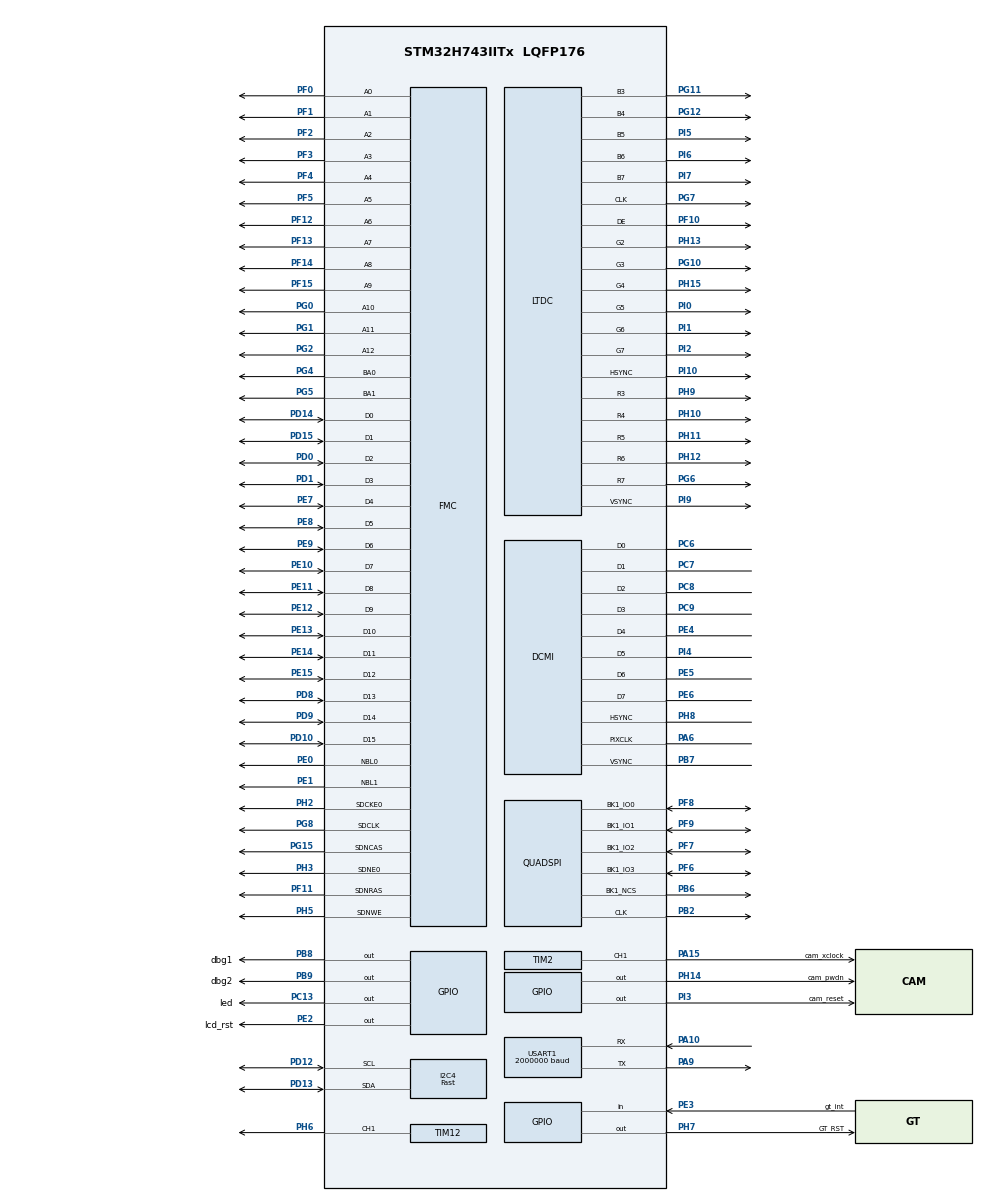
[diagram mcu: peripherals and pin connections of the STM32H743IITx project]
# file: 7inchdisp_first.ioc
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CORTEX_M7.AccessPermission_S-Cortex_Memory_Protection_Unit_Region1_Settings_S=MPU_REGION_FULL_ACCESS
CORTEX_M7.AccessPermission_S-Cortex_Memory_Protection_Unit_Region2_Settings_S=MPU_REGION_FULL_ACCESS
CORTEX_M7.BaseAddress_S-Cortex_Memory_Protection_Unit_Region1_Settings_S=0xc0000000
CORTEX_M7.BaseAddress_S-Cortex_Memory_Protection_Unit_Region2_Settings_S=0x90000000
CORTEX_M7.CPU_DCache=Enabled
CORTEX_M7.CPU_ICache=Enabled
CORTEX_M7.Enable_S-Cortex_Memory_Protection_Unit_Region1_Settings_S=MPU_REGION_ENABLE
CORTEX_M7.Enable_S-Cortex_Memory_Protection_Unit_Region2_Settings_S=MPU_REGION_ENABLE
CORTEX_M7.IsBufferable_S-Cortex_Memory_Protection_Unit_Region1_Settings_S=MPU_ACCESS_BUFFERABLE
CORTEX_M7.IsBufferable_S-Cortex_Memory_Protection_Unit_Region2_Settings_S=MPU_ACCESS_BUFFERABLE
CORTEX_M7.IsCacheable_S-Cortex_Memory_Protection_Unit_Region1_Settings_S=MPU_ACCESS_CACHEABLE
CORTEX_M7.IsCacheable_S-Cortex_Memory_Protection_Unit_Region2_Settings_S=MPU_ACCESS_CACHEABLE
CORTEX_M7.Size_S-Cortex_Memory_Protection_Unit_Region1_Settings_S=MPU_REGION_SIZE_32MB
CORTEX_M7.Size_S-Cortex_Memory_Protection_Unit_Region2_Settings_S=MPU_REGION_SIZE_16MB
CORTEX_M7.default_mode_Activation=1
DCMI.PCKPolarity=DCMI_PCKPOLARITY_RISING
DCMI.VSPolarity=DCMI_VSPOLARITY_HIGH
DMA2D.ColorMode=DMA2D_OUTPUT_RGB565
Dma.DCMI.1.Direction=DMA_PERIPH_TO_MEMORY
Dma.DCMI.1.EventEnable=DISABLE
Dma.DCMI.1.FIFOMode=DMA_FIFOMODE_ENABLE
Dma.DCMI.1.FIFOThreshold=DMA_FIFO_THRESHOLD_FULL
Dma.DCMI.1.Instance=DMA1_Stream1
Dma.DCMI.1.MemBurst=DMA_MBURST_INC4
Dma.DCMI.1.MemDataAlignment=DMA_MDATAALIGN_WORD
Dma.DCMI.1.MemInc=DMA_MINC_ENABLE
Dma.DCMI.1.Mode=DMA_CIRCULAR
Dma.DCMI.1.PeriphBurst=DMA_PBURST_SINGLE
Dma.DCMI.1.PeriphDataAlignment=DMA_PDATAALIGN_WORD
Dma.DCMI.1.PeriphInc=DMA_PINC_DISABLE
Dma.DCMI.1.Polarity=HAL_DMAMUX_REQ_GEN_RISING
Dma.DCMI.1.Priority=DMA_PRIORITY_VERY_HIGH
Dma.DCMI.1.RequestNumber=1
Dma.DCMI.1.SignalID=NONE
Dma.DCMI.1.SyncEnable=DISABLE
Dma.DCMI.1.SyncPolarity=HAL_DMAMUX_SYNC_NO_EVENT
Dma.DCMI.1.SyncRequestNumber=1
Dma.DCMI.1.SyncSignalID=NONE
Dma.Request0=USART1_RX
Dma.Request1=DCMI
Dma.USART1_RX.0.Direction=DMA_PERIPH_TO_MEMORY
Dma.USART1_RX.0.EventEnable=DISABLE
Dma.USART1_RX.0.FIFOMode=DMA_FIFOMODE_ENABLE
Dma.USART1_RX.0.FIFOThreshold=DMA_FIFO_THRESHOLD_FULL
Dma.USART1_RX.0.Instance=DMA1_Stream0
Dma.USART1_RX.0.MemBurst=DMA_MBURST_SINGLE
Dma.USART1_RX.0.MemDataAlignment=DMA_MDATAALIGN_BYTE
Dma.USART1_RX.0.MemInc=DMA_MINC_ENABLE
Dma.USART1_RX.0.Mode=DMA_NORMAL
Dma.USART1_RX.0.PeriphBurst=DMA_PBURST_SINGLE
Dma.USART1_RX.0.PeriphDataAlignment=DMA_PDATAALIGN_BYTE
Dma.USART1_RX.0.PeriphInc=DMA_PINC_DISABLE
Dma.USART1_RX.0.Polarity=HAL_DMAMUX_REQ_GEN_RISING
Dma.USART1_RX.0.Priority=DMA_PRIORITY_LOW
Dma.USART1_RX.0.RequestNumber=1
Dma.USART1_RX.0.SignalID=NONE
Dma.USART1_RX.0.SyncEnable=DISABLE
Dma.USART1_RX.0.SyncPolarity=HAL_DMAMUX_SYNC_NO_EVENT
Dma.USART1_RX.0.SyncRequestNumber=1
Dma.USART1_RX.0.SyncSignalID=NONE
FMC.CASLatency1=FMC_SDRAM_CAS_LATENCY_3
FMC.ColumnBitsNumber1=FMC_SDRAM_COLUMN_BITS_NUM_9
FMC.ExitSelfRefreshDelay1=7
FMC.LoadToActiveDelay1=2
FMC.RCDDelay1=2
FMC.RPDelay1=2
FMC.RPDelay2=2
FMC.ReadBurst1=FMC_SDRAM_RBURST_ENABLE
FMC.ReadBurst2=FMC_SDRAM_RBURST_ENABLE
FMC.ReadPipeDelay1=FMC_SDRAM_RPIPE_DELAY_1
FMC.ReadPipeDelay2=FMC_SDRAM_RPIPE_DELAY_1
FMC.RowCycleDelay1=7
FMC.RowCycleDelay2=7
FMC.SDClockPeriod1=FMC_SDRAM_CLOCK_PERIOD_2
FMC.SDClockPeriod2=FMC_SDRAM_CLOCK_PERIOD_2
FMC.SelfRefreshTime1=5
FMC.WriteRecoveryTime1=3
I2C4.I2C_Speed_Mode=I2C_Fast
I2C4.Timing=0x009034B6
LTDC.ActiveH=600
LTDC.ActiveW=1024
LTDC.Alpha_L0=255
LTDC.DEPolarity=LTDC_DEPOLARITY_AL
LTDC.FBStartAdress_L0=0xc0000000
LTDC.Green=255
LTDC.HBP=40
LTDC.HFP=31
LTDC.HSync=10
LTDC.ImageHeight_L0=600
LTDC.ImageWidth_L0=1024
LTDC.Layers=0
LTDC.PCPolarity=LTDC_PCPOLARITY_IPC
LTDC.PixelFormat_L0=LTDC_PIXEL_FORMAT_RGB565
LTDC.Red_L0=255
LTDC.VBP=20
LTDC.VFP=10
LTDC.VSync=5
LTDC.WindowX1_L0=1024
LTDC.WindowY1_L0=600
Mcu.Family=STM32H7
Mcu.Name=STM32H743IITx
Mcu.Package=LQFP176
NVIC.DCMI_IRQn=true\:0\:0\:false\:false\:true\:true\:true\:true
NVIC.DMA1_Stream0_IRQn=true\:0\:0\:false\:false\:true\:false\:true\:true
NVIC.DMA1_Stream1_IRQn=true\:0\:0\:false\:false\:true\:false\:true\:true
NVIC.PriorityGroup=NVIC_PRIORITYGROUP_4
NVIC.QUADSPI_IRQn=true\:0\:0\:false\:false\:true\:true\:true\:true
PA10.Mode=Asynchronous
PA10.Signal=USART1_RX
PA13\ (JTMS/SWDIO).Mode=Trace_Asynchronous_SW
PA13\ (JTMS/SWDIO).Signal=DEBUG_JTMS-SWDIO
PA14\ (JTCK/SWCLK).Mode=Trace_Asynchronous_SW
PA14\ (JTCK/SWCLK).Signal=DEBUG_JTCK-SWCLK
PA15\ (JTDI).GPIO_Label=cam_xclock
PA15\ (JTDI).GPIO_Speed=GPIO_SPEED_FREQ_HIGH
PA15\ (JTDI).Signal=S_TIM2_CH1_ETR
PA6.Mode=Slave_8_bits_External_Synchro
PA6.Signal=DCMI_PIXCLK
PA9.Mode=Asynchronous
PA9.Signal=USART1_TX
PB2.GPIO_Speed=GPIO_SPEED_FREQ_VERY_HIGH
PB2.Mode=Single Bank 1
PB2.Signal=QUADSPI_CLK
PB3\ (JTDO/TRACESWO).Mode=Trace_Asynchronous_SW
PB3\ (JTDO/TRACESWO).Signal=DEBUG_JTDO-SWO
PB6.GPIO_FM6=__NULL
PB6.GPIO_Speed=GPIO_SPEED_FREQ_VERY_HIGH
PB6.Mode=Single Bank 1
PB6.Signal=QUADSPI_BK1_NCS
PB7.Mode=Slave_8_bits_External_Synchro
PB7.Signal=DCMI_VSYNC
PB8.GPIO_Label=dbg1
PB8.Signal=GPIO_Output
PB9.GPIO_Label=dbg2
PB9.Signal=GPIO_Output
PC13.GPIO_Label=led
PC13.Signal=GPIO_Output
PC6.Mode=Slave_8_bits_External_Synchro
PC6.Signal=DCMI_D0
PC7.Mode=Slave_8_bits_External_Synchro
PC7.Signal=DCMI_D1
PC8.Mode=Slave_8_bits_External_Synchro
PC8.Signal=DCMI_D2
PC9.Mode=Slave_8_bits_External_Synchro
PC9.Signal=DCMI_D3
PD0.Signal=FMC_D2_DA2
PD1.Signal=FMC_D3_DA3
PD10.Signal=FMC_D15_DA15
PD12.Mode=I2C
PD12.Signal=I2C4_SCL
PD13.Mode=I2C
PD13.Signal=I2C4_SDA
PD14.Signal=FMC_D0_DA0
PD15.Signal=FMC_D1_DA1
PD8.Signal=FMC_D13_DA13
PD9.Signal=FMC_D14_DA14
PE0.Signal=FMC_NBL0
PE1.Signal=FMC_NBL1
PE10.Signal=FMC_D7_DA7
PE11.Signal=FMC_D8_DA8
PE12.Signal=FMC_D9_DA9
PE13.Signal=FMC_D10_DA10
PE14.Signal=FMC_D11_DA11
PE15.Signal=FMC_D12_DA12
PE2.GPIO_Label=lcd_rst
PE2.Signal=GPIO_Output
PE3.GPIO_Label=gt_int
PE3.Signal=GPIO_Input
PE4.Mode=Slave_8_bits_External_Synchro
PE4.Signal=DCMI_D4
PE5.Mode=Slave_8_bits_External_Synchro
PE5.Signal=DCMI_D6
PE6.Mode=Slave_8_bits_External_Synchro
PE6.Signal=DCMI_D7
PE7.Signal=FMC_D4_DA4
PE8.Signal=FMC_D5_DA5
PE9.Signal=FMC_D6_DA6
PF0.Signal=FMC_A0
PF1.Signal=FMC_A1
PF10.Mode=RGB565
PF10.Signal=LTDC_DE
PF11.Signal=FMC_SDNRAS
PF12.Signal=FMC_A6
PF13.Signal=FMC_A7
PF14.Signal=FMC_A8
PF15.Signal=FMC_A9
PF2.Signal=FMC_A2
PF3.Signal=FMC_A3
PF4.Signal=FMC_A4
PF5.Signal=FMC_A5
PF6.GPIO_Speed=GPIO_SPEED_FREQ_VERY_HIGH
PF6.Mode=Single Bank 1
PF6.Signal=QUADSPI_BK1_IO3
PF7.GPIO_Speed=GPIO_SPEED_FREQ_VERY_HIGH
PF7.Mode=Single Bank 1
PF7.Signal=QUADSPI_BK1_IO2
PF8.GPIO_Speed=GPIO_SPEED_FREQ_VERY_HIGH
PF8.Mode=Single Bank 1
PF8.Signal=QUADSPI_BK1_IO0
PF9.GPIO_Speed=GPIO_SPEED_FREQ_VERY_HIGH
PF9.Mode=Single Bank 1
PF9.Signal=QUADSPI_BK1_IO1
PG0.Signal=FMC_A10
PG1.Signal=FMC_A11
PG10.Mode=RGB565
PG10.Signal=LTDC_G3
PG11.Mode=RGB565
PG11.Signal=LTDC_B3
PG12.Mode=RGB565
PG12.Signal=LTDC_B4
PG15.Signal=FMC_SDNCAS
PG2.Signal=FMC_A12
PG4.Signal=FMC_A14_BA0
PG5.Signal=FMC_A15_BA1
PG6.Mode=RGB565
PG6.Signal=LTDC_R7
PG7.Mode=RGB565
PG7.Signal=LTDC_CLK
PG8.Signal=FMC_SDCLK
PH0-OSC_IN\ (PH0).Mode=HSE-External-Oscillator
PH0-OSC_IN\ (PH0).Signal=RCC_OSC_IN
PH1-OSC_OUT\ (PH1).Mode=HSE-External-Oscillator
PH1-OSC_OUT\ (PH1).Signal=RCC_OSC_OUT
PH10.Mode=RGB565
PH10.Signal=LTDC_R4
PH11.Mode=RGB565
PH11.Signal=LTDC_R5
PH12.Mode=RGB565
PH12.Signal=LTDC_R6
PH13.Mode=RGB565
PH13.Signal=LTDC_G2
PH14.GPIO_Label=cam_pwdn
PH14.Signal=GPIO_Output
PH15.Mode=RGB565
PH15.Signal=LTDC_G4
PH2.Mode=SdramChipSelect1_1
PH2.Signal=FMC_SDCKE0
PH3.Mode=SdramChipSelect1_1
PH3.Signal=FMC_SDNE0
PH5.Signal=FMC_SDNWE
PH6.Signal=S_TIM12_CH1
PH7.GPIO_Label=GT_RST
PH7.Signal=GPIO_Output
PH8.Mode=Slave_8_bits_External_Synchro
PH8.Signal=DCMI_HSYNC
PH9.Mode=RGB565
PH9.Signal=LTDC_R3
PI0.Mode=RGB565
PI0.Signal=LTDC_G5
PI1.Mode=RGB565
PI1.Signal=LTDC_G6
PI10.Mode=RGB565
PI10.Signal=LTDC_HSYNC
PI2.Mode=RGB565
PI2.Signal=LTDC_G7
PI3.GPIO_Label=cam_reset
PI3.Signal=GPIO_Output
PI4.Mode=Slave_8_bits_External_Synchro
PI4.Signal=DCMI_D5
PI5.Mode=RGB565
PI5.Signal=LTDC_B5
PI6.Mode=RGB565
PI6.Signal=LTDC_B6
PI7.Mode=RGB565
PI7.Signal=LTDC_B7
PI9.Mode=RGB565
PI9.Signal=LTDC_VSYNC
ProjectManager.HeapSize=0x200
ProjectManager.StackSize=0x400
ProjectManager.TargetToolchain=STM32CubeIDE
QUADSPI.ChipSelectHighTime=QSPI_CS_HIGH_TIME_2_CYCLE
QUADSPI.ClockPrescaler=1
QUADSPI.FifoThreshold=32
QUADSPI.FlashSize=23
QUADSPI.SampleShifting=QSPI_SAMPLE_SHIFTING_HALFCYCLE
RCC.ADCCLockSelection=RCC_ADCCLKSOURCE_PLL2
RCC.ADCFreq_Value=50390625
RCC.APB1Freq_Value=100000000
RCC.APB2Freq_Value=100000000
RCC.APB3Freq_Value=100000000
RCC.APB4Freq_Value=100000000
RCC.CECCLockSelection=RCC_CECCLKSOURCE_LSI
RCC.CKPERSourceSelection=RCC_CLKPSOURCE_HSI
RCC.CSI_VALUE=4000000
RCC.CortexFreq_Value=400000000
RCC.Cortex_Div=SYSTICK_CLKSOURCE_HCLK
RCC.Cortex_DivARG=SystemCoreClock/1000
RCC.D1CPRE=RCC_SYSCLK_DIV1
RCC.D1PPRE=RCC_APB3_DIV2
RCC.D2PPRE1=RCC_APB1_DIV2
RCC.D2PPRE2=RCC_APB2_DIV2
RCC.D3PPRE=RCC_APB4_DIV2
RCC.DFSDMCLockSelection=RCC_DFSDM1CLKSOURCE_D2PCLK1
RCC.DIVM1=5
RCC.DIVM2=32
RCC.DIVM3=5
RCC.DIVN1=160
RCC.DIVN2=129
RCC.DIVN3=159
RCC.DIVP1=2
RCC.DIVP2=2
RCC.DIVP3=2
RCC.DIVQ1=4
RCC.DIVQ2=2
RCC.DIVQ3=2
RCC.DIVR1=2
RCC.DIVR2=2
RCC.DIVR3=44
RCC.DSICLockSelection=RCC_DSICLKSOURCE_PHY
RCC.DSIPHY_Div=8
RCC.DSITX_Div=4
RCC.DSI_PHY_VALUE=12288000
RCC.EXTERNAL_CLOCK_VALUE=12288000
RCC.FDCANCLockSelection=RCC_FDCANCLKSOURCE_PLL
RCC.FLatency-AdvancedSettings=FLASH_LATENCY_0
RCC.FMCCLockSelection=RCC_FMCCLKSOURCE_D1HCLK
RCC.HCLKFreq_Value=200000000
RCC.HPRE=RCC_HCLK_DIV2
RCC.HSE_VALUE=25000000
RCC.HSIDiv=RCC_PLLSAIDIVR_1
RCC.HSI_VALUE=64000000
RCC.I2C123CLockSelection=RCC_I2C123CLKSOURCE_D2PCLK1
RCC.I2C4CLockSelection=RCC_I2C4CLKSOURCE_D3PCLK1
RCC.LPTIM1CLockSelection=RCC_LPTIM1CLKSOURCE_D2PCLK1
RCC.LPTIM2CLockSelection=RCC_LPTIM2CLKSOURCE_D3PCLK1
RCC.LPTIM345CLockSelection=RCC_LPTIM345CLKSOURCE_D3PCLK1
RCC.LPUART1CLockSelection=RCC_LPUART1CLKSOURCE_D3PCLK1
RCC.LSE_VALUE=32768
RCC.PLL1_VCI_Range-AdvancedSettings=RCC_PLL1VCIRANGE_3
RCC.PLL2_VCI_Range-AdvancedSettings=RCC_PLL2VCIRANGE_0
RCC.PLL3_VCI_Range-AdvancedSettings=RCC_PLL3VCIRANGE_2
RCC.PLLDSIDev=2
RCC.PLLDSIIDF=DSI_PLL_IN_DIV1
RCC.PLLDSIMult=2
RCC.PLLDSINDIV=20
RCC.PLLDSIODF=DSI_PLL_OUT_DIV1
RCC.PLLSourceVirtual=RCC_PLLSOURCE_HSE
RCC.QSPICLockSelection=RCC_QSPICLKSOURCE_D1HCLK
RCC.RC48_VALUE=48000000
RCC.RCC_MCO1Source=RCC_MCO1SOURCE_HSI48
RCC.RCC_MCO2Source=RCC_MCO2SOURCE_SYSCLK
RCC.RCC_MCODiv1=RCC_MCODIV_2
RCC.RCC_MCODiv2=RCC_MCODIV_1
RCC.RCC_RTC_Clock_Source_FROM_HSE=RCC_RTCCLKSOURCE_HSE_DIV2
RCC.RNGCLockSelection=RCC_RNGCLKSOURCE_HSI48
RCC.SAI1CLockSelection=RCC_SAI1CLKSOURCE_PLL
RCC.SAI23CLockSelection=RCC_SAI23CLKSOURCE_PLL
RCC.SAI4ACLockSelection=RCC_SAI4ACLKSOURCE_PLL
RCC.SAI4BCLockSelection=RCC_SAI4BCLKSOURCE_PLL
RCC.SPDIFCLockSelection=RCC_SPDIFRXCLKSOURCE_PLL
RCC.SPI123CLockSelection=RCC_SPI123CLKSOURCE_PLL
RCC.SPI6CLockSelection=RCC_SPI6CLKSOURCE_D3PCLK1
RCC.SWPCLockSelection=RCC_SWPMI1CLKSOURCE_D2PCLK1
RCC.SYSCLKFreq_VALUE=400000000
RCC.SYSCLKSource=RCC_SYSCLKSOURCE_PLLCLK
RCC.Spi45ClockSelection=RCC_SPI45CLKSOURCE_D2PCLK1
RCC.USART16CLockSelection=RCC_USART16CLKSOURCE_D2PCLK2
RCC.USART234578CLockSelection=RCC_USART234578CLKSOURCE_D2PCLK1
RCC.USBCLockSelection=RCC_USBCLKSOURCE_PLL
RCC.USBFreq_Value=200000000
SH.FMC_A0.0=FMC_A0,13b-sda1
SH.FMC_A1.0=FMC_A1,13b-sda1
SH.FMC_A10.0=FMC_A10,13b-sda1
SH.FMC_A11.0=FMC_A11,13b-sda1
SH.FMC_A12.0=FMC_A12,13b-sda1
SH.FMC_A14_BA0.0=FMC_BA0,FourSdramBanks1
SH.FMC_A15_BA1.0=FMC_BA1,FourSdramBanks1
SH.FMC_A2.0=FMC_A2,13b-sda1
SH.FMC_A3.0=FMC_A3,13b-sda1
SH.FMC_A4.0=FMC_A4,13b-sda1
SH.FMC_A5.0=FMC_A5,13b-sda1
SH.FMC_A6.0=FMC_A6,13b-sda1
SH.FMC_A7.0=FMC_A7,13b-sda1
SH.FMC_A8.0=FMC_A8,13b-sda1
SH.FMC_A9.0=FMC_A9,13b-sda1
SH.FMC_D0_DA0.0=FMC_D0,sd-16b-d1
SH.FMC_D10_DA10.0=FMC_D10,sd-16b-d1
SH.FMC_D11_DA11.0=FMC_D11,sd-16b-d1
SH.FMC_D12_DA12.0=FMC_D12,sd-16b-d1
SH.FMC_D13_DA13.0=FMC_D13,sd-16b-d1
SH.FMC_D14_DA14.0=FMC_D14,sd-16b-d1
SH.FMC_D15_DA15.0=FMC_D15,sd-16b-d1
SH.FMC_D1_DA1.0=FMC_D1,sd-16b-d1
SH.FMC_D2_DA2.0=FMC_D2,sd-16b-d1
SH.FMC_D3_DA3.0=FMC_D3,sd-16b-d1
SH.FMC_D4_DA4.0=FMC_D4,sd-16b-d1
SH.FMC_D5_DA5.0=FMC_D5,sd-16b-d1
SH.FMC_D6_DA6.0=FMC_D6,sd-16b-d1
SH.FMC_D7_DA7.0=FMC_D7,sd-16b-d1
SH.FMC_D8_DA8.0=FMC_D8,sd-16b-d1
SH.FMC_D9_DA9.0=FMC_D9,sd-16b-d1
SH.FMC_NBL0.0=FMC_NBL0,Sd2ByteEnable1
SH.FMC_NBL1.0=FMC_NBL1,Sd2ByteEnable1
SH.FMC_SDCLK.0=FMC_SDCLK,13b-sda1
SH.FMC_SDNCAS.0=FMC_SDNCAS,13b-sda1
SH.FMC_SDNRAS.0=FMC_SDNRAS,13b-sda1
SH.FMC_SDNWE.0=FMC_SDNWE,13b-sda1
SH.S_TIM12_CH1.0=TIM12_CH1,PWM Generation1 CH1
SH.S_TIM2_CH1_ETR.0=TIM2_CH1,PWM Generation1 CH1
TIM12.Channel-PWM\ Generation1\ CH1=TIM_CHANNEL_1
TIM12.Period=1666
TIM12.Prescaler=199
TIM12.Pulse-PWM\ Generation1\ CH1=833
TIM2.Channel-PWM\ Generation1\ CH1=TIM_CHANNEL_1
TIM2.Period=7
TIM2.Prescaler=1
TIM2.Pulse-PWM\ Generation1\ CH1=4
USART1.BaudRate=2000000
USART1.FIFOMode=FIFOMODE_ENABLE
USART1.Parity=PARITY_EVEN
USART1.VirtualMode-Asynchronous=VM_ASYNC
USART1.WordLength=WORDLENGTH_9B
VP_DMA2D_VS_DMA2D.Mode=DMA2D_Activate
VP_MEMORYMAP_VS_MEMORYMAP.Mode=CurAppReg
VP_TIM12_VS_ClockSourceINT.Mode=Internal
board=custom

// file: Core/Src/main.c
/* USER CODE BEGIN Header */
/**
 ******************************************************************************
 * @file           : main.c
 * @brief          : Main program body
 ******************************************************************************
 * @attention
 *
 * Copyright (c) 2025 STMicroelectronics.
 * All rights reserved.
 *
 * This software is licensed under terms that can be found in the LICENSE file
 * in the root directory of this software component.
 * If no LICENSE file comes with this software, it is provided AS-IS.
 *
 ******************************************************************************
 */
/* USER CODE END Header */
#include "main.h"

/* USER CODE BEGIN Includes */
#include <stdio.h>
#include "camera.h"
#include "ov7670.h"
/* USER CODE END Includes */

DCMI_HandleTypeDef hdcmi;
DMA_HandleTypeDef hdma_dcmi;

DMA2D_HandleTypeDef hdma2d;

I2C_HandleTypeDef hi2c4;

LTDC_HandleTypeDef hltdc;

QSPI_HandleTypeDef hqspi;

TIM_HandleTypeDef htim2;
TIM_HandleTypeDef htim12;

UART_HandleTypeDef huart1;
DMA_HandleTypeDef hdma_usart1_rx;

SDRAM_HandleTypeDef hsdram1;

/* USER CODE BEGIN PV */

__attribute__((section(".sdramb0")))  uint32_t volatile framebuffer[1024 * 600 * 2
		/ 4]; // Example RGB565
__attribute__((section(".sdramb1")))  uint32_t volatile cambuffer[640 * 480 * 2 / 4]; // Example RGB565

uint8_t volatile camera_regs[0xc9 + 1];

/* USER CODE END PV */

void SystemClock_Config(void);
static void MPU_Config(void);
static void MX_GPIO_Init(void);
static void MX_DMA_Init(void);
static void MX_USART1_UART_Init(void);
static void MX_FMC_Init(void);
static void MX_LTDC_Init(void);
static void MX_I2C4_Init(void);
static void MX_TIM12_Init(void);
static void MX_QUADSPI_Init(void);
static void MX_DCMI_Init(void);
static void MX_TIM2_Init(void);
static void MX_DMA2D_Init(void);

/* USER CODE BEGIN 0 */
void sdram_init(void) {
	FMC_SDRAM_CommandTypeDef command;

	// Step 1: Enable clock
	command.CommandMode = FMC_SDRAM_CMD_CLK_ENABLE;
	command.CommandTarget = FMC_SDRAM_CMD_TARGET_BANK1;
	command.AutoRefreshNumber = 1;
	command.ModeRegisterDefinition = 0;
	HAL_SDRAM_SendCommand(&hsdram1, &command, 0x1000);
	HAL_Delay(1); // >100 µs

	// Step 2: Precharge all
	command.CommandMode = FMC_SDRAM_CMD_PALL;
	HAL_SDRAM_SendCommand(&hsdram1, &command, 0x1000);

	// Step 3: Auto-refresh (2 cycles)
	command.CommandMode = FMC_SDRAM_CMD_AUTOREFRESH_MODE;
	command.AutoRefreshNumber = 2;
	HAL_SDRAM_SendCommand(&hsdram1, &command, 0x1000);

	// Step 4: Load Mode Register
	uint32_t mode_reg = 0 | (0x0 << 0)  // Burst Length = 1
			| (0x0 << 3)  // Burst Type = Sequential
			| (0x3 << 4)  // CAS Latency = 3
			| (0x0 << 7)  // Standard Operation
			| (0x1 << 9); // Write burst = Single

	command.CommandMode = FMC_SDRAM_CMD_LOAD_MODE;
	command.ModeRegisterDefinition = mode_reg;
	HAL_SDRAM_SendCommand(&hsdram1, &command, 0x1000);

	// Step 5: Set refresh rate
	HAL_SDRAM_ProgramRefreshRate(&hsdram1, 780);

}

int __io_putchar(int ch) {
	HAL_UART_Transmit(&huart1, (uint8_t*) &ch, 1, HAL_MAX_DELAY);
	return ch;
}

#define SDRAM_START ((uint32_t)0xC0000000)   // SDRAM Bank1 base
#define SDRAM_SIZE  ((uint32_t)0x02000000)   // 32 MB for W9825G6KH (16M x16)
#define SDRAM_END   (SDRAM_START + SDRAM_SIZE)

static inline uint32_t* sdram_ptr(uint32_t offset) {
	return (uint32_t*) (SDRAM_START + offset);
}

int sdram_memtest(void) {
	uint32_t errors = 0;
	uint32_t addr;
	uint32_t readback;

	printf("SDRAM test: 0x%08lX .. 0x%08lX\n", (unsigned long) SDRAM_START,
			(unsigned long) SDRAM_END - 1);

	// 1. Walking bit test
	for (uint32_t bit = 0; bit < 32; bit++) {
		uint32_t pattern = 1UL << bit;
		*sdram_ptr(0) = pattern;
		readback = *sdram_ptr(0);
		if (readback != pattern) {
			printf(
					"Walking bit error at bit %lu: wrote 0x%08lX, read 0x%08lX\n",
					(unsigned long) bit, (unsigned long) pattern,
					(unsigned long) readback);
			errors++;
		}
	}

	// 2. Address test
	for (addr = 0; addr < SDRAM_SIZE; addr += 4) {
		*sdram_ptr(addr) = addr ^ 0xAAAAAAAA;
	}
	for (addr = 0; addr < SDRAM_SIZE; addr += 4) {
		readback = *sdram_ptr(addr);
		if (readback != (addr ^ 0xAAAAAAAA)) {
			printf(
					"Address test error at 0x%08lX: wrote 0x%08lX, read 0x%08lX\n",
					(unsigned long) (SDRAM_START + addr),
					(unsigned long) (addr ^ 0xAAAAAAAA),
					(unsigned long) readback);
			errors++;
			break;
		}
	}

	// 3. Pattern test
	const uint32_t patterns[] = { 0x00000000, 0xFFFFFFFF, 0xAAAAAAAA,
			0x55555555, 0x12345678, 0x87654321 };
	for (int p = 0; p < (int) (sizeof(patterns) / sizeof(patterns[0])); p++) {
		uint32_t pat = patterns[p];
		printf("Pattern 0x%08lX ... ", (unsigned long) pat);

		for (addr = 0; addr < SDRAM_SIZE; addr += 4) {
			*sdram_ptr(addr) = pat;
		}
		for (addr = 0; addr < SDRAM_SIZE; addr += 4) {
			readback = *sdram_ptr(addr);
			if (readback != pat) {
				printf(
						"\nPattern error at 0x%08lX: wrote 0x%08lX, read 0x%08lX\n",
						(unsigned long) (SDRAM_START + addr),
						(unsigned long) pat, (unsigned long) readback);
				errors++;
				break;
			}
		}
		printf("done\n");
	}

	if (errors == 0) {
		printf("SDRAM test passed.\n");
		return 0;
	} else {
		printf("SDRAM test failed with %lu errors.\n", (unsigned long) errors);
		return -1;
	}
}

#define SDRAM_BASE_ADDR 0xC0000000
#undef SDRAM_SIZE
#define SDRAM_SIZE      (32*1024*1024) // 32 MB
#define SDRAM_WORDS     (SDRAM_SIZE / 4)

typedef enum {
	TEST_PATTERN_FIXED,
	TEST_PATTERN_WALKING_ONES,
	TEST_PATTERN_WALKING_ZEROS,
	TEST_PATTERN_ALTERNATING,
	TEST_PATTERN_RANDOM
} TestPattern;

static inline uint32_t prng(uint32_t *state) {
	// simple 32-bit LCG pseudo-random generator
	*state = *state * 1664525 + 1013904223;
	return *state;
}

// Perform one pass with a single pattern
int SDRAM_Test_Pattern(uint32_t *mem, TestPattern pattern) {
	uint32_t state = 0x12345678;
	uint32_t write_val = 0;

	for (uint32_t i = 0; i < SDRAM_WORDS; i++) {
		switch (pattern) {
		case TEST_PATTERN_FIXED:
			write_val = 0xA5A5A5A5;
			break;
		case TEST_PATTERN_WALKING_ONES:
			write_val = 1U << (i % 32);
			break;
		case TEST_PATTERN_WALKING_ZEROS:
			write_val = ~(1U << (i % 32));
			break;
		case TEST_PATTERN_ALTERNATING:
			write_val = (i % 2) ? 0xAAAAAAAA : 0x55555555;
			break;
		case TEST_PATTERN_RANDOM:
			write_val = prng(&state);
			break;
		}
		mem[i] = write_val;
	}

	// Ensure all writes are visible in D-Cache
	SCB_CleanDCache_by_Addr((uint32_t*) mem, SDRAM_SIZE);
	state = 0x12345678;

	for (uint32_t i = 0; i < SDRAM_WORDS; i++) {
		switch (pattern) {
		case TEST_PATTERN_FIXED:
			write_val = 0xA5A5A5A5;
			break;
		case TEST_PATTERN_WALKING_ONES:
			write_val = 1U << (i % 32);
			break;
		case TEST_PATTERN_WALKING_ZEROS:
			write_val = ~(1U << (i % 32));
			break;
		case TEST_PATTERN_ALTERNATING:
			write_val = (i % 2) ? 0xAAAAAAAA : 0x55555555;
			break;
		case TEST_PATTERN_RANDOM:
			write_val = prng(&state);
			break;
		}
		uint32_t read_val = mem[i];
		SCB_InvalidateDCache_by_Addr((uint32_t*) &mem[i], 4);
		if (read_val != write_val) {
			return i; // first failing index
		}
	}

	return -1; // passed
}

// Full SDRAM memory test with multiple patterns
void SDRAM_FullTest(void) {
	uint32_t *mem = (uint32_t*) SDRAM_BASE_ADDR;
	int res;

	TestPattern patterns[] = { TEST_PATTERN_FIXED, TEST_PATTERN_WALKING_ONES,
			TEST_PATTERN_WALKING_ZEROS, TEST_PATTERN_ALTERNATING,
			TEST_PATTERN_RANDOM };

	for (int p = 0; p < sizeof(patterns) / sizeof(patterns[0]); p++) {
		res = SDRAM_Test_Pattern(mem, patterns[p]);
		if (res < 0)
			printf("Pattern %d passed\n", p);
		else
			printf("Pattern %d failed at address 0x%08X\n", p,
			SDRAM_BASE_ADDR + res * 4);
	}
}

typedef enum {
	PATTERN_FIXED,
	PATTERN_WALKING_ONES,
	PATTERN_WALKING_ZEROS,
	PATTERN_ALTERNATING,
	PATTERN_RANDOM
} TestPattern2;

typedef enum {
	ACCESS_8BIT = 8, ACCESS_16BIT = 16, ACCESS_32BIT = 32
} AccessSize;

// Fill SDRAM with a pattern
void SDRAM_Fill(uint32_t base, TestPattern2 pattern, AccessSize size,
		uint32_t seed) {
	uint32_t state = seed;
	for (uint32_t offset = 0; offset < SDRAM_SIZE; offset += (size / 8)) {
		uint32_t val = 0;
		switch (pattern) {
		case PATTERN_FIXED:
			val = 0xA5A5A5A5;
			break;
		case PATTERN_WALKING_ONES:
			val = 1U << ((offset / size * 8) % 32);
			break;
		case PATTERN_WALKING_ZEROS:
			val = ~(1U << ((offset / size * 8) % 32));
			break;
		case PATTERN_ALTERNATING:
			val = ((offset / (size / 8)) % 2) ? 0xAAAAAAAA : 0x55555555;
			break;
		case PATTERN_RANDOM:
			val = prng(&state);
			break;
		}

		switch (size) {
		case ACCESS_8BIT:
			*((volatile uint8_t*) (base + offset)) = (uint8_t) val;
			break;
		case ACCESS_16BIT:
			*((volatile uint16_t*) (base + offset)) = (uint16_t) val;
			break;
		case ACCESS_32BIT:
			*((volatile uint32_t*) (base + offset)) = val;
			break;
		}
	}

	// Ensure all writes hit SDRAM
	SCB_CleanDCache_by_Addr((uint32_t*) base, SDRAM_SIZE);
}

// Verify SDRAM pattern
int SDRAM_Verify(uint32_t base, TestPattern2 pattern, AccessSize size,
		uint32_t seed) {
	uint32_t state = seed;
	for (uint32_t offset = 0; offset < SDRAM_SIZE; offset += (size / 8)) {
		uint32_t expected = 0;
		switch (pattern) {
		case PATTERN_FIXED:
			expected = 0xA5A5A5A5;
			break;
		case PATTERN_WALKING_ONES:
			expected = 1U << ((offset / size * 8) % 32);
			break;
		case PATTERN_WALKING_ZEROS:
			expected = ~(1U << ((offset / size * 8) % 32));
			break;
		case PATTERN_ALTERNATING:
			expected = ((offset / (size / 8)) % 2) ? 0xAAAAAAAA : 0x55555555;
			break;
		case PATTERN_RANDOM:
			expected = prng(&state);
			break;
		}

		uint32_t read_val = 0;
		switch (size) {
		case ACCESS_8BIT:
			read_val = *((volatile uint8_t*) (base + offset));
			break;
		case ACCESS_16BIT:
			read_val = *((volatile uint16_t*) (base + offset));
			break;
		case ACCESS_32BIT:
			read_val = *((volatile uint32_t*) (base + offset));
			break;
		}

		SCB_InvalidateDCache_by_Addr((uint32_t*) (base + offset), size / 8);

		if (read_val != (expected & ((1UL << size) - 1))) {
			return offset; // first failing address
		}
	}
	return -1; // passed
}

// Run full SDRAM test
void SDRAM_FullTest2(void) {
	TestPattern2 patterns[] = { PATTERN_FIXED, PATTERN_WALKING_ONES,
			PATTERN_WALKING_ZEROS, PATTERN_ALTERNATING, PATTERN_RANDOM };
	AccessSize sizes[] = { ACCESS_8BIT, ACCESS_16BIT, ACCESS_32BIT };
	uint32_t seed = 0x12345678;

	for (int p = 0; p < sizeof(patterns) / sizeof(patterns[0]); p++) {
		for (int s = 0; s < sizeof(sizes) / sizeof(sizes[0]); s++) {
			SDRAM_Fill(SDRAM_BASE_ADDR, patterns[p], sizes[s], seed);
			int fail = SDRAM_Verify(SDRAM_BASE_ADDR, patterns[p], sizes[s],
					seed);
			if (fail < 0)
				printf("Pattern %d, Access %d-bit: PASS\n", p,
						(s == 0 ? 8 : (s == 1 ? 16 : 32)));
			else
				printf("Pattern %d, Access %d-bit: FAIL at 0x%08X\n", p,
						(s == 0 ? 8 : (s == 1 ? 16 : 32)),
						SDRAM_BASE_ADDR + fail);
		}
	}
}

extern void run_memory_benchmarks(void);
extern void run_dma_benchmarks(void);

#define QSPI_FLASH_MEM_ADDR       0x90000000

#define QSPI_FLASH_SIZE           25

#define QSPI_FLASH_SECTOR_SIZE    (4*1024)
#define QSPI_FLASH_PAGE_SIZE      (256)
#define QSPI_FLASH_END_ADDR       (1<<QSPI_FLASH_SIZE)
#define QSPI_FLASH_BYTE_SIZE      (16*1024*1024)

typedef enum {
	BQB_Cmd_ReadID = 0x9F,
	BQB_Cmd_ReadStatus1 = 0x05,
	BQB_Cmd_WriteEnable = 0x06,
	BQB_Cmd_SectorErase = 0x20,
	BQB_Cmd_ChipErase = 0xC7,
	BQB_Cmd_PageProgram_Quad = 0x32,
	BQB_Cmd_FastRead_Quad = 0xEB,
} BQB_Cmd_E;

int BspQspiBoot_Init(void) {
	uint32_t i;
	char *p;

	/* ½«¾ä±úÊÖ¶¯ÇåÁã£¬·ÀÖ¹×÷ÎªÈ«¾Ö±äÁ¿µÄÊ±ºòÃ»ÓÐÇåÁã */
	p = (char*) &hqspi;
	for (i = 0; i < sizeof(QSPI_HandleTypeDef); i++) {
		*p++ = 0;
	}

	/* ¸´Î»QSPI */
	hqspi.Instance = QUADSPI;

	if (HAL_QSPI_DeInit(&hqspi) != HAL_OK) {
		return 1;
	}

	/* ÉèÖÃÊ±ÖÓËÙ¶È£¬QSPI clock = 200MHz / (ClockPrescaler+1) = 100MHz */
	hqspi.Init.ClockPrescaler = 1;

	/* ÉèÖÃFIFO·§Öµ£¬·¶Î§1 - 32 */
	hqspi.Init.FifoThreshold = 1;

	/*
	 QUADSPIÔÚFLASHÇý¶¯ÐÅºÅºó¹ý°ë¸öCLKÖÜÆÚ²Å¶ÔFLASHÇý¶¯µÄÊý¾Ý²ÉÑù¡£
	 ÔÚÍâ²¿ÐÅºÅÑÓ³ÙÊ±£¬ÕâÓÐÀûÓÚÍÆ³ÙÊý¾Ý²ÉÑù¡£
	 */
	hqspi.Init.SampleShifting = QSPI_SAMPLE_SHIFTING_HALFCYCLE;

	/* Flash´óÐ¡ÊÇ2^(FlashSize + 1) = 2^23 = 8MB */
	hqspi.Init.FlashSize = QSPI_FLASH_SIZE; //QSPI_FLASH_SIZE - 1; 2020-03-04, ÐèÒªÀ©´óÒ»±¶£¬·ñÔòÄÚ´æÓ³Éä·½Î»×îºó1¸öµØÖ·Ê±£¬»áÒì³£

	/* ÃüÁîÖ®¼äµÄCSÆ¬Ñ¡ÖÁÉÙ±£³Ö1¸öÊ±ÖÓÖÜÆÚµÄ¸ßµçÆ½ */
	hqspi.Init.ChipSelectHighTime = QSPI_CS_HIGH_TIME_2_CYCLE; //QSPI_CS_HIGH_TIME_5_CYCLE

	/*
	 MODE0: ±íÊ¾Æ¬Ñ¡ÐÅºÅ¿ÕÏÐÆÚ¼ä£¬CLKÊ±ÖÓÐÅºÅÊÇµÍµçÆ½
	 MODE3: ±íÊ¾Æ¬Ñ¡ÐÅºÅ¿ÕÏÐÆÚ¼ä£¬CLKÊ±ÖÓÐÅºÅÊÇ¸ßµçÆ½
	 */
	hqspi.Init.ClockMode = QSPI_CLOCK_MODE_0;

	/* QSPIÓÐÁ½¸öBANK£¬ÕâÀïÊ¹ÓÃµÄBANK1 */
	hqspi.Init.FlashID = QSPI_FLASH_ID_1;

	/* Ê¹ÓÃÁËBANK1£¬ÕâÀïÊÇ½ûÖ¹Ë«BANK */
	hqspi.Init.DualFlash = QSPI_DUALFLASH_DISABLE;

	/* ³õÊ¼»¯ÅäÖÃQSPI */
	if (HAL_QSPI_Init(&hqspi) != HAL_OK) {
		return 1;
	}

	return 0;
}

int BspQspiBoot_MemMapped(void) {
	QSPI_CommandTypeDef s_command = { 0 };
	QSPI_MemoryMappedTypeDef s_mem_mapped_cfg = { 0 };

	s_command.InstructionMode = QSPI_INSTRUCTION_1_LINE; /* 1Ïß·½Ê½·¢ËÍÖ¸Áî */
	s_command.AddressSize = QSPI_ADDRESS_24_BITS; /* 24Î»µØÖ· */
	s_command.AlternateByteMode = QSPI_ALTERNATE_BYTES_NONE; /* ÎÞ½»Ìæ×Ö½Ú */
	s_command.DdrMode = QSPI_DDR_MODE_DISABLE; /* W25Q64JV²»Ö§³ÖDDR */
	s_command.DdrHoldHalfCycle = QSPI_DDR_HHC_ANALOG_DELAY; /* DDRÄ£Ê½£¬Êý¾ÝÊä³öÑÓ³Ù */
	s_command.SIOOMode = QSPI_SIOO_INST_EVERY_CMD; /* Ã¿´Î´«Êä¶¼·¢Ö¸Áî */

	s_command.Instruction = BQB_Cmd_FastRead_Quad; /* ¿ìËÙ¶ÁÈ¡ÃüÁî */
	s_command.AddressMode = QSPI_ADDRESS_4_LINES; /* 4¸öµØÖ·Ïß */
	s_command.DataMode = QSPI_DATA_4_LINES; /* 4¸öÊý¾ÝÏß */
	s_command.DummyCycles = 6; /* ¿ÕÖÜÆÚ */

	s_mem_mapped_cfg.TimeOutActivation = QSPI_TIMEOUT_COUNTER_DISABLE;
	s_mem_mapped_cfg.TimeOutPeriod = 0;

	if (HAL_QSPI_MemoryMapped(&hqspi, &s_command, &s_mem_mapped_cfg)
			!= HAL_OK) {
		return 1;
	}

	return 0;
}

extern int print_sd_info(void);
extern void print_sd_card_info(void);
extern void print_sd_card_details(void);
volatile int retest = 0;
extern void sd_read_benchmark(void);

void HAL_DCMI_FrameEventCallback(DCMI_HandleTypeDef *hdcmi) {
	/* Frame complete */
	//frame_ready_flag = 1;   // set a flag
	HAL_GPIO_TogglePin(led_GPIO_Port, led_Pin);
	ITM->PORT[0].u8 = 'C';

	HAL_DMA2D_Start(&hdma2d, (uint32_t) cambuffer,      // source
					(uint32_t) framebuffer,    // destination
					640,                       // width in pixels
					480);                      // height in pixels
}

void myDMA2D_Init(void) {
	hdma2d.Instance = DMA2D;
	hdma2d.Init.Mode = DMA2D_M2M;             // Memory-to-memory
	hdma2d.Init.ColorMode = DMA2D_RGB565;     // Destination format
	hdma2d.Init.OutputOffset = 1024 - 640;   // framebuffer width - camera width
	hdma2d.LayerCfg[1].InputOffset = 0;       // No input offset
	hdma2d.LayerCfg[1].InputColorMode = DMA2D_INPUT_RGB565;
	hdma2d.LayerCfg[1].AlphaMode = DMA2D_NO_MODIF_ALPHA;
	hdma2d.LayerCfg[1].InputAlpha = 0xFF;

	if (HAL_DMA2D_Init(&hdma2d) != HAL_OK)
		Error_Handler();
	if (HAL_DMA2D_ConfigLayer(&hdma2d, 1) != HAL_OK)
		Error_Handler();
}

volatile int reReadRegs = 0;
volatile int reWriteReg = 0;
volatile uint8_t caddr = 0, cdata = 0;
/* USER CODE END 0 */

int main(void)
{

  /* MPU Configuration--------------------------------------------------------*/
  MPU_Config();

  /* Enable the CPU Cache */

  /* Enable I-Cache---------------------------------------------------------*/
  SCB_EnableICache();

  /* Enable D-Cache---------------------------------------------------------*/
  SCB_EnableDCache();

  /* MCU Configuration--------------------------------------------------------*/

  /* Reset of all peripherals, Initializes the Flash interface and the Systick. */
  HAL_Init();

  /* Configure the system clock */
  SystemClock_Config();

  /* USER CODE BEGIN SysInit */
	//BspQspiBoot_Init();
  /* USER CODE END SysInit */

  /* Initialize all configured peripherals */
  MX_GPIO_Init();
  MX_DMA_Init();
  MX_USART1_UART_Init();
  MX_FMC_Init();
  MX_LTDC_Init();
  MX_I2C4_Init();
  MX_TIM12_Init();
  MX_QUADSPI_Init();
  MX_DCMI_Init();
  MX_TIM2_Init();
  MX_DMA2D_Init();
  /* USER CODE BEGIN 2 */
	//print_sd_info();
	//print_sd_card_info();
	//HAL_SD_CardCSDTypeDef myCSD;
	//HAL_SD_CardCIDTypeDef myCID;
	//HAL_SD_GetCardCSD(&hsd2, &myCSD);
	//print_sd_card_details();

	//HAL_SD_GetCardCID(&hsd2,&myCID);
	//uint32_t qspi_id = BspQspiBoot_ReadID();
	//printf("qspi id= %08x\n",qspi_id);
	BspQspiBoot_MemMapped();
	//BspQspiBoot_MemMapped();
	//HAL_UART_Transmit(&huart1, "Start\n", 6, 100);
	printf("Start\n");

	sdram_init();
	printf("SDRAM inited\n");

//	sd_read_benchmark();

	printf("Starting memtest\n");
	{
		volatile uint32_t *p = (uint32_t*) 0xC0000000;
		for (uint32_t i = 0; i < 32 * 1024 * 1024 / 4; i++) {
			p[i] = 0xA5A5A5A5;      // write pattern
			if (p[i] != 0xA5A5A5A5) {
				// report fault, address = &p[i]
				printf("fault at %08x:%04x\n", &p[i], p[i]);
				break;
			}
		}

	}
	//sdram_memtest();
	//SDRAM_FullTest();
	//SDRAM_FullTest2();
	HAL_GPIO_WritePin(lcd_rst_GPIO_Port, lcd_rst_Pin, 1);
	run_memory_benchmarks();
	run_dma_benchmarks();
	__HAL_LTDC_ENABLE(&hltdc);
	__HAL_LTDC_RELOAD_CONFIG(&hltdc); // reload shadow registers
	__HAL_LTDC_LAYER_ENABLE(&hltdc, 0);
	//HAL_GPIO_WritePin(LCD_BL_GPIO_Port,LCD_BL_Pin,1);

	HAL_TIM_PWM_Start(&htim12, TIM_CHANNEL_1);
	__HAL_TIM_SET_COMPARE(&htim12, TIM_CHANNEL_1, 833);

	HAL_TIM_PWM_Start(&htim2, TIM_CHANNEL_1);
	HAL_Delay(10);
	HAL_GPIO_WritePin(cam_reset_GPIO_Port, cam_reset_Pin, 1);
	HAL_Delay(20);

	myDMA2D_Init();

	Camera_Init_Device(&hi2c4, FRAMESIZE_VGA);
	OV7670_Config();
	OV7670_ReadRegList(camera_regs);

	HAL_DCMI_Start_DMA(&hdcmi, DCMI_MODE_CONTINUOUS, (uint32_t) cambuffer,640*480 * 2 / 4);

	//memset(0xc0000000,0xf0,1024*600*1);
	{
		uint32_t *src_sdram = (uint16_t*) 0xC0000000;
		for (int i = 0; i < 1024 * 600; i++) {
			*src_sdram++ = i;
		}
	}
	SCB_CleanDCache_by_Addr((uint32_t*) 0xc0000000, 1024 * 600 * 2);
	//restore u:\work\2025\7inchdispcolor\ws\7inchdisp_first\tools\testimg1.bin binary 0xC0000000

	ITM->TCR = ITM_TCR_ITMENA_Msk | ITM_TCR_SYNCENA_Msk;
	ITM->TER = 3; // enable port 0

  /* USER CODE END 2 */

  /* Infinite loop */
  /* USER CODE BEGIN WHILE */
	while (1) {
		HAL_UART_Transmit(&huart1, ".", 1, 100);
		HAL_Delay(33);
		//HAL_GPIO_TogglePin(led_GPIO_Port, led_Pin);
		ITM->PORT[1].u8 = 'M';
#if 0
		HAL_DMA2D_Start(&hdma2d, (uint32_t) cambuffer,      // source
				(uint32_t) framebuffer,    // destination
				640,                       // width in pixels
				480);                      // height in pixels
#endif
		HAL_DMA2D_PollForTransfer(&hdma2d, HAL_MAX_DELAY);
		//dump memory camimg.bin 0xC012c000 0xC012c000 + 0x96000
		//dump memory camimg2.bin 0xc0800000 0xc0800000 + 0x96000
		//dump memory screen.bin 0xc0000000 0xc0000000 + 0x12c000

		if (reReadRegs){
			reReadRegs = 0;
			int res = OV7670_ReadRegList(camera_regs);
			printf("OV7670_ReadRegList = %d\n", res);
		}
		if (reWriteReg) {
			reWriteReg = 0;
			int res = OV7670_WriteReg(caddr, &cdata);
			printf("OV7670_WriteReg = %d\n", res);
		}

    /* USER CODE END WHILE */

	}
}

void SystemClock_Config(void)
{
  RCC_OscInitTypeDef RCC_OscInitStruct = {0};
  RCC_ClkInitTypeDef RCC_ClkInitStruct = {0};

  /** Supply configuration update enable
  */
  HAL_PWREx_ConfigSupply(PWR_LDO_SUPPLY);

  /** Configure the main internal regulator output voltage
  */
  __HAL_PWR_VOLTAGESCALING_CONFIG(PWR_REGULATOR_VOLTAGE_SCALE1);

  while(!__HAL_PWR_GET_FLAG(PWR_FLAG_VOSRDY)) {}

  /** Initializes the RCC Oscillators according to the specified parameters
  * in the RCC_OscInitTypeDef structure.
  */
  RCC_OscInitStruct.OscillatorType = RCC_OSCILLATORTYPE_HSE;
  RCC_OscInitStruct.HSEState = RCC_HSE_ON;
  RCC_OscInitStruct.PLL.PLLState = RCC_PLL_ON;
  RCC_OscInitStruct.PLL.PLLSource = RCC_PLLSOURCE_HSE;
  RCC_OscInitStruct.PLL.PLLM = 5;
  RCC_OscInitStruct.PLL.PLLN = 160;
  RCC_OscInitStruct.PLL.PLLP = 2;
  RCC_OscInitStruct.PLL.PLLQ = 4;
  RCC_OscInitStruct.PLL.PLLR = 2;
  RCC_OscInitStruct.PLL.PLLRGE = RCC_PLL1VCIRANGE_2;
  RCC_OscInitStruct.PLL.PLLVCOSEL = RCC_PLL1VCOWIDE;
  RCC_OscInitStruct.PLL.PLLFRACN = 0;
  if (HAL_RCC_OscConfig(&RCC_OscInitStruct) != HAL_OK)
  {
    Error_Handler();
  }

  /** Initializes the CPU, AHB and APB buses clocks
  */
  RCC_ClkInitStruct.ClockType = RCC_CLOCKTYPE_HCLK|RCC_CLOCKTYPE_SYSCLK
                              |RCC_CLOCKTYPE_PCLK1|RCC_CLOCKTYPE_PCLK2
                              |RCC_CLOCKTYPE_D3PCLK1|RCC_CLOCKTYPE_D1PCLK1;
  RCC_ClkInitStruct.SYSCLKSource = RCC_SYSCLKSOURCE_PLLCLK;
  RCC_ClkInitStruct.SYSCLKDivider = RCC_SYSCLK_DIV1;
  RCC_ClkInitStruct.AHBCLKDivider = RCC_HCLK_DIV2;
  RCC_ClkInitStruct.APB3CLKDivider = RCC_APB3_DIV2;
  RCC_ClkInitStruct.APB1CLKDivider = RCC_APB1_DIV2;
  RCC_ClkInitStruct.APB2CLKDivider = RCC_APB2_DIV2;
  RCC_ClkInitStruct.APB4CLKDivider = RCC_APB4_DIV2;

  if (HAL_RCC_ClockConfig(&RCC_ClkInitStruct, FLASH_LATENCY_2) != HAL_OK)
  {
    Error_Handler();
  }
}

static void MX_DCMI_Init(void)
{

  hdcmi.Instance = DCMI;
  hdcmi.Init.SynchroMode = DCMI_SYNCHRO_HARDWARE;
  hdcmi.Init.PCKPolarity = DCMI_PCKPOLARITY_RISING;
  hdcmi.Init.VSPolarity = DCMI_VSPOLARITY_HIGH;
  hdcmi.Init.HSPolarity = DCMI_HSPOLARITY_LOW;
  hdcmi.Init.CaptureRate = DCMI_CR_ALL_FRAME;
  hdcmi.Init.ExtendedDataMode = DCMI_EXTEND_DATA_8B;
  hdcmi.Init.JPEGMode = DCMI_JPEG_DISABLE;
  hdcmi.Init.ByteSelectMode = DCMI_BSM_ALL;
  hdcmi.Init.ByteSelectStart = DCMI_OEBS_ODD;
  hdcmi.Init.LineSelectMode = DCMI_LSM_ALL;
  hdcmi.Init.LineSelectStart = DCMI_OELS_ODD;
  if (HAL_DCMI_Init(&hdcmi) != HAL_OK)
  {
    Error_Handler();
  }

}

static void MX_DMA2D_Init(void)
{

  hdma2d.Instance = DMA2D;
  hdma2d.Init.Mode = DMA2D_M2M;
  hdma2d.Init.ColorMode = DMA2D_OUTPUT_RGB565;
  hdma2d.Init.OutputOffset = 0;
  hdma2d.LayerCfg[1].InputOffset = 0;
  hdma2d.LayerCfg[1].InputColorMode = DMA2D_INPUT_RGB565;
  hdma2d.LayerCfg[1].AlphaMode = DMA2D_NO_MODIF_ALPHA;
  hdma2d.LayerCfg[1].InputAlpha = 0;
  hdma2d.LayerCfg[1].AlphaInverted = DMA2D_REGULAR_ALPHA;
  hdma2d.LayerCfg[1].RedBlueSwap = DMA2D_RB_REGULAR;
  hdma2d.LayerCfg[1].ChromaSubSampling = DMA2D_NO_CSS;
  if (HAL_DMA2D_Init(&hdma2d) != HAL_OK)
  {
    Error_Handler();
  }
  if (HAL_DMA2D_ConfigLayer(&hdma2d, 1) != HAL_OK)
  {
    Error_Handler();
  }

}

static void MX_I2C4_Init(void)
{

  hi2c4.Instance = I2C4;
  hi2c4.Init.Timing = 0x009034B6;
  hi2c4.Init.OwnAddress1 = 0;
  hi2c4.Init.AddressingMode = I2C_ADDRESSINGMODE_7BIT;
  hi2c4.Init.DualAddressMode = I2C_DUALADDRESS_DISABLE;
  hi2c4.Init.OwnAddress2 = 0;
  hi2c4.Init.OwnAddress2Masks = I2C_OA2_NOMASK;
  hi2c4.Init.GeneralCallMode = I2C_GENERALCALL_DISABLE;
  hi2c4.Init.NoStretchMode = I2C_NOSTRETCH_DISABLE;
  if (HAL_I2C_Init(&hi2c4) != HAL_OK)
  {
    Error_Handler();
  }

  /** Configure Analogue filter
  */
  if (HAL_I2CEx_ConfigAnalogFilter(&hi2c4, I2C_ANALOGFILTER_ENABLE) != HAL_OK)
  {
    Error_Handler();
  }

  /** Configure Digital filter
  */
  if (HAL_I2CEx_ConfigDigitalFilter(&hi2c4, 0) != HAL_OK)
  {
    Error_Handler();
  }

}

static void MX_LTDC_Init(void)
{

  LTDC_LayerCfgTypeDef pLayerCfg = {0};

  hltdc.Instance = LTDC;
  hltdc.Init.HSPolarity = LTDC_HSPOLARITY_AL;
  hltdc.Init.VSPolarity = LTDC_VSPOLARITY_AL;
  hltdc.Init.DEPolarity = LTDC_DEPOLARITY_AL;
  hltdc.Init.PCPolarity = LTDC_PCPOLARITY_IPC;
  hltdc.Init.HorizontalSync = 9;
  hltdc.Init.VerticalSync = 4;
  hltdc.Init.AccumulatedHBP = 49;
  hltdc.Init.AccumulatedVBP = 24;
  hltdc.Init.AccumulatedActiveW = 1073;
  hltdc.Init.AccumulatedActiveH = 624;
  hltdc.Init.TotalWidth = 1104;
  hltdc.Init.TotalHeigh = 634;
  hltdc.Init.Backcolor.Blue = 0;
  hltdc.Init.Backcolor.Green = 255;
  hltdc.Init.Backcolor.Red = 0;
  if (HAL_LTDC_Init(&hltdc) != HAL_OK)
  {
    Error_Handler();
  }
  pLayerCfg.WindowX0 = 0;
  pLayerCfg.WindowX1 = 1024;
  pLayerCfg.WindowY0 = 0;
  pLayerCfg.WindowY1 = 600;
  pLayerCfg.PixelFormat = LTDC_PIXEL_FORMAT_RGB565;
  pLayerCfg.Alpha = 255;
  pLayerCfg.Alpha0 = 0;
  pLayerCfg.BlendingFactor1 = LTDC_BLENDING_FACTOR1_CA;
  pLayerCfg.BlendingFactor2 = LTDC_BLENDING_FACTOR2_CA;
  pLayerCfg.FBStartAdress = 0xc0000000;
  pLayerCfg.ImageWidth = 1024;
  pLayerCfg.ImageHeight = 600;
  pLayerCfg.Backcolor.Blue = 0;
  pLayerCfg.Backcolor.Green = 0;
  pLayerCfg.Backcolor.Red = 255;
  if (HAL_LTDC_ConfigLayer(&hltdc, &pLayerCfg, 0) != HAL_OK)
  {
    Error_Handler();
  }

}

static void MX_QUADSPI_Init(void)
{

  /* QUADSPI parameter configuration*/
  hqspi.Instance = QUADSPI;
  hqspi.Init.ClockPrescaler = 1;
  hqspi.Init.FifoThreshold = 32;
  hqspi.Init.SampleShifting = QSPI_SAMPLE_SHIFTING_HALFCYCLE;
  hqspi.Init.FlashSize = 23;
  hqspi.Init.ChipSelectHighTime = QSPI_CS_HIGH_TIME_2_CYCLE;
  hqspi.Init.ClockMode = QSPI_CLOCK_MODE_0;
  hqspi.Init.FlashID = QSPI_FLASH_ID_1;
  hqspi.Init.DualFlash = QSPI_DUALFLASH_DISABLE;
  if (HAL_QSPI_Init(&hqspi) != HAL_OK)
  {
    Error_Handler();
  }

}

static void MX_TIM2_Init(void)
{

  TIM_MasterConfigTypeDef sMasterConfig = {0};
  TIM_OC_InitTypeDef sConfigOC = {0};

  htim2.Instance = TIM2;
  htim2.Init.Prescaler = 1;
  htim2.Init.CounterMode = TIM_COUNTERMODE_UP;
  htim2.Init.Period = 7;
  htim2.Init.ClockDivision = TIM_CLOCKDIVISION_DIV1;
  htim2.Init.AutoReloadPreload = TIM_AUTORELOAD_PRELOAD_DISABLE;
  if (HAL_TIM_PWM_Init(&htim2) != HAL_OK)
  {
    Error_Handler();
  }
  sMasterConfig.MasterOutputTrigger = TIM_TRGO_RESET;
  sMasterConfig.MasterSlaveMode = TIM_MASTERSLAVEMODE_DISABLE;
  if (HAL_TIMEx_MasterConfigSynchronization(&htim2, &sMasterConfig) != HAL_OK)
  {
    Error_Handler();
  }
  sConfigOC.OCMode = TIM_OCMODE_PWM1;
  sConfigOC.Pulse = 4;
  sConfigOC.OCPolarity = TIM_OCPOLARITY_HIGH;
  sConfigOC.OCFastMode = TIM_OCFAST_DISABLE;
  if (HAL_TIM_PWM_ConfigChannel(&htim2, &sConfigOC, TIM_CHANNEL_1) != HAL_OK)
  {
    Error_Handler();
  }
  HAL_TIM_MspPostInit(&htim2);

}

static void MX_TIM12_Init(void)
{

  TIM_ClockConfigTypeDef sClockSourceConfig = {0};
  TIM_MasterConfigTypeDef sMasterConfig = {0};
  TIM_OC_InitTypeDef sConfigOC = {0};

  htim12.Instance = TIM12;
  htim12.Init.Prescaler = 199;
  htim12.Init.CounterMode = TIM_COUNTERMODE_UP;
  htim12.Init.Period = 1666;
  htim12.Init.ClockDivision = TIM_CLOCKDIVISION_DIV1;
  htim12.Init.AutoReloadPreload = TIM_AUTORELOAD_PRELOAD_DISABLE;
  if (HAL_TIM_Base_Init(&htim12) != HAL_OK)
  {
    Error_Handler();
  }
  sClockSourceConfig.ClockSource = TIM_CLOCKSOURCE_INTERNAL;
  if (HAL_TIM_ConfigClockSource(&htim12, &sClockSourceConfig) != HAL_OK)
  {
    Error_Handler();
  }
  if (HAL_TIM_PWM_Init(&htim12) != HAL_OK)
  {
    Error_Handler();
  }
  sMasterConfig.MasterOutputTrigger = TIM_TRGO_RESET;
  sMasterConfig.MasterSlaveMode = TIM_MASTERSLAVEMODE_DISABLE;
  if (HAL_TIMEx_MasterConfigSynchronization(&htim12, &sMasterConfig) != HAL_OK)
  {
    Error_Handler();
  }
  sConfigOC.OCMode = TIM_OCMODE_PWM1;
  sConfigOC.Pulse = 833;
  sConfigOC.OCPolarity = TIM_OCPOLARITY_HIGH;
  sConfigOC.OCFastMode = TIM_OCFAST_DISABLE;
  if (HAL_TIM_PWM_ConfigChannel(&htim12, &sConfigOC, TIM_CHANNEL_1) != HAL_OK)
  {
    Error_Handler();
  }
  HAL_TIM_MspPostInit(&htim12);

}

static void MX_USART1_UART_Init(void)
{

  huart1.Instance = USART1;
  huart1.Init.BaudRate = 2000000;
  huart1.Init.WordLength = UART_WORDLENGTH_9B;
  huart1.Init.StopBits = UART_STOPBITS_1;
  huart1.Init.Parity = UART_PARITY_EVEN;
  huart1.Init.Mode = UART_MODE_TX_RX;
  huart1.Init.HwFlowCtl = UART_HWCONTROL_NONE;
  huart1.Init.OverSampling = UART_OVERSAMPLING_16;
  huart1.Init.OneBitSampling = UART_ONE_BIT_SAMPLE_DISABLE;
  huart1.Init.ClockPrescaler = UART_PRESCALER_DIV1;
  huart1.AdvancedInit.AdvFeatureInit = UART_ADVFEATURE_NO_INIT;
  if (HAL_UART_Init(&huart1) != HAL_OK)
  {
    Error_Handler();
  }
  if (HAL_UARTEx_SetTxFifoThreshold(&huart1, UART_TXFIFO_THRESHOLD_1_8) != HAL_OK)
  {
    Error_Handler();
  }
  if (HAL_UARTEx_SetRxFifoThreshold(&huart1, UART_RXFIFO_THRESHOLD_1_8) != HAL_OK)
  {
    Error_Handler();
  }
  if (HAL_UARTEx_EnableFifoMode(&huart1) != HAL_OK)
  {
    Error_Handler();
  }

}

static void MX_DMA_Init(void)
{

  /* DMA controller clock enable */
  __HAL_RCC_DMA1_CLK_ENABLE();

  /* DMA interrupt init */
  /* DMA1_Stream0_IRQn interrupt configuration */
  HAL_NVIC_SetPriority(DMA1_Stream0_IRQn, 0, 0);
  HAL_NVIC_EnableIRQ(DMA1_Stream0_IRQn);
  /* DMA1_Stream1_IRQn interrupt configuration */
  HAL_NVIC_SetPriority(DMA1_Stream1_IRQn, 0, 0);
  HAL_NVIC_EnableIRQ(DMA1_Stream1_IRQn);

}

/* FMC initialization function */
static void MX_FMC_Init(void)
{

  FMC_SDRAM_TimingTypeDef SdramTiming = {0};

  /** Perform the SDRAM1 memory initialization sequence
  */
  hsdram1.Instance = FMC_SDRAM_DEVICE;
  /* hsdram1.Init */
  hsdram1.Init.SDBank = FMC_SDRAM_BANK1;
  hsdram1.Init.ColumnBitsNumber = FMC_SDRAM_COLUMN_BITS_NUM_9;
  hsdram1.Init.RowBitsNumber = FMC_SDRAM_ROW_BITS_NUM_13;
  hsdram1.Init.MemoryDataWidth = FMC_SDRAM_MEM_BUS_WIDTH_16;
  hsdram1.Init.InternalBankNumber = FMC_SDRAM_INTERN_BANKS_NUM_4;
  hsdram1.Init.CASLatency = FMC_SDRAM_CAS_LATENCY_3;
  hsdram1.Init.WriteProtection = FMC_SDRAM_WRITE_PROTECTION_DISABLE;
  hsdram1.Init.SDClockPeriod = FMC_SDRAM_CLOCK_PERIOD_2;
  hsdram1.Init.ReadBurst = FMC_SDRAM_RBURST_ENABLE;
  hsdram1.Init.ReadPipeDelay = FMC_SDRAM_RPIPE_DELAY_1;
  /* SdramTiming */
  SdramTiming.LoadToActiveDelay = 2;
  SdramTiming.ExitSelfRefreshDelay = 7;
  SdramTiming.SelfRefreshTime = 5;
  SdramTiming.RowCycleDelay = 7;
  SdramTiming.WriteRecoveryTime = 3;
  SdramTiming.RPDelay = 2;
  SdramTiming.RCDDelay = 2;

  if (HAL_SDRAM_Init(&hsdram1, &SdramTiming) != HAL_OK)
  {
    Error_Handler( );
  }

}

static void MX_GPIO_Init(void)
{
  GPIO_InitTypeDef GPIO_InitStruct = {0};

  /* GPIO Ports Clock Enable */
  __HAL_RCC_GPIOE_CLK_ENABLE();
  __HAL_RCC_GPIOC_CLK_ENABLE();
  __HAL_RCC_GPIOI_CLK_ENABLE();
  __HAL_RCC_GPIOF_CLK_ENABLE();
  __HAL_RCC_GPIOH_CLK_ENABLE();
  __HAL_RCC_GPIOA_CLK_ENABLE();
  __HAL_RCC_GPIOB_CLK_ENABLE();
  __HAL_RCC_GPIOG_CLK_ENABLE();
  __HAL_RCC_GPIOD_CLK_ENABLE();

  /*Configure GPIO pin Output Level */
  HAL_GPIO_WritePin(lcd_rst_GPIO_Port, lcd_rst_Pin, GPIO_PIN_RESET);

  /*Configure GPIO pin Output Level */
  HAL_GPIO_WritePin(led_GPIO_Port, led_Pin, GPIO_PIN_RESET);

  /*Configure GPIO pin Output Level */
  HAL_GPIO_WritePin(GPIOH, GT_RST_Pin|cam_pwdn_Pin, GPIO_PIN_RESET);

  /*Configure GPIO pin Output Level */
  HAL_GPIO_WritePin(cam_reset_GPIO_Port, cam_reset_Pin, GPIO_PIN_RESET);

  /*Configure GPIO pin Output Level */
  HAL_GPIO_WritePin(GPIOB, dbg1_Pin|dbg2_Pin, GPIO_PIN_RESET);

  /*Configure GPIO pin : lcd_rst_Pin */
  GPIO_InitStruct.Pin = lcd_rst_Pin;
  GPIO_InitStruct.Mode = GPIO_MODE_OUTPUT_PP;
  GPIO_InitStruct.Pull = GPIO_NOPULL;
  GPIO_InitStruct.Speed = GPIO_SPEED_FREQ_LOW;
  HAL_GPIO_Init(lcd_rst_GPIO_Port, &GPIO_InitStruct);

  /*Configure GPIO pin : gt_int_Pin */
  GPIO_InitStruct.Pin = gt_int_Pin;
  GPIO_InitStruct.Mode = GPIO_MODE_INPUT;
  GPIO_InitStruct.Pull = GPIO_NOPULL;
  HAL_GPIO_Init(gt_int_GPIO_Port, &GPIO_InitStruct);

  /*Configure GPIO pin : led_Pin */
  GPIO_InitStruct.Pin = led_Pin;
  GPIO_InitStruct.Mode = GPIO_MODE_OUTPUT_PP;
  GPIO_InitStruct.Pull = GPIO_NOPULL;
  GPIO_InitStruct.Speed = GPIO_SPEED_FREQ_LOW;
  HAL_GPIO_Init(led_GPIO_Port, &GPIO_InitStruct);

  /*Configure GPIO pins : GT_RST_Pin cam_pwdn_Pin */
  GPIO_InitStruct.Pin = GT_RST_Pin|cam_pwdn_Pin;
  GPIO_InitStruct.Mode = GPIO_MODE_OUTPUT_PP;
  GPIO_InitStruct.Pull = GPIO_NOPULL;
  GPIO_InitStruct.Speed = GPIO_SPEED_FREQ_LOW;
  HAL_GPIO_Init(GPIOH, &GPIO_InitStruct);

  /*Configure GPIO pin : cam_reset_Pin */
  GPIO_InitStruct.Pin = cam_reset_Pin;
  GPIO_InitStruct.Mode = GPIO_MODE_OUTPUT_PP;
  GPIO_InitStruct.Pull = GPIO_NOPULL;
  GPIO_InitStruct.Speed = GPIO_SPEED_FREQ_LOW;
  HAL_GPIO_Init(cam_reset_GPIO_Port, &GPIO_InitStruct);

  /*Configure GPIO pins : dbg1_Pin dbg2_Pin */
  GPIO_InitStruct.Pin = dbg1_Pin|dbg2_Pin;
  GPIO_InitStruct.Mode = GPIO_MODE_OUTPUT_PP;
  GPIO_InitStruct.Pull = GPIO_NOPULL;
  GPIO_InitStruct.Speed = GPIO_SPEED_FREQ_LOW;
  HAL_GPIO_Init(GPIOB, &GPIO_InitStruct);

}

 /* MPU Configuration */

void MPU_Config(void)
{
  MPU_Region_InitTypeDef MPU_InitStruct = {0};

  /* Disables the MPU */
  HAL_MPU_Disable();

  /** Initializes and configures the Region and the memory to be protected
  */
  MPU_InitStruct.Enable = MPU_REGION_ENABLE;
  MPU_InitStruct.Number = MPU_REGION_NUMBER0;
  MPU_InitStruct.BaseAddress = 0x0;
  MPU_InitStruct.Size = MPU_REGION_SIZE_4GB;
  MPU_InitStruct.SubRegionDisable = 0x87;
  MPU_InitStruct.TypeExtField = MPU_TEX_LEVEL0;
  MPU_InitStruct.AccessPermission = MPU_REGION_NO_ACCESS;
  MPU_InitStruct.DisableExec = MPU_INSTRUCTION_ACCESS_DISABLE;
  MPU_InitStruct.IsShareable = MPU_ACCESS_SHAREABLE;
  MPU_InitStruct.IsCacheable = MPU_ACCESS_NOT_CACHEABLE;
  MPU_InitStruct.IsBufferable = MPU_ACCESS_NOT_BUFFERABLE;

  HAL_MPU_ConfigRegion(&MPU_InitStruct);

  /** Initializes and configures the Region and the memory to be protected
  */
  MPU_InitStruct.Number = MPU_REGION_NUMBER1;
  MPU_InitStruct.BaseAddress = 0xc0000000;
  MPU_InitStruct.Size = MPU_REGION_SIZE_32MB;
  MPU_InitStruct.SubRegionDisable = 0x0;
  MPU_InitStruct.AccessPermission = MPU_REGION_FULL_ACCESS;
  MPU_InitStruct.DisableExec = MPU_INSTRUCTION_ACCESS_ENABLE;
  MPU_InitStruct.IsShareable = MPU_ACCESS_NOT_SHAREABLE;
  MPU_InitStruct.IsCacheable = MPU_ACCESS_CACHEABLE;
  MPU_InitStruct.IsBufferable = MPU_ACCESS_BUFFERABLE;

  HAL_MPU_ConfigRegion(&MPU_InitStruct);

  /** Initializes and configures the Region and the memory to be protected
  */
  MPU_InitStruct.Number = MPU_REGION_NUMBER2;
  MPU_InitStruct.BaseAddress = 0x90000000;
  MPU_InitStruct.Size = MPU_REGION_SIZE_16MB;

  HAL_MPU_ConfigRegion(&MPU_InitStruct);
  /* Enables the MPU */
  HAL_MPU_Enable(MPU_PRIVILEGED_DEFAULT);

}

void Error_Handler(void)
{
	__disable_irq();
	while (1) {
	}
}
